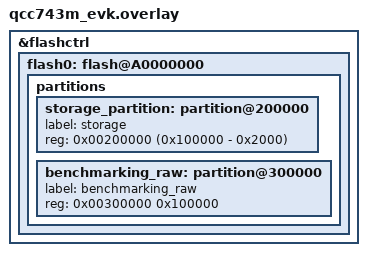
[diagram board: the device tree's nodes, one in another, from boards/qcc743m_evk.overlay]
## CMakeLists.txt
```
# Copyright (c) 2026 Qualcomm Technologies, Inc. and/or its subsidiaries
# SPDX-License-Identifier: BSD-3-Clause

cmake_minimum_required(VERSION 3.20.0)
find_package(Zephyr REQUIRED HINTS $ENV{ZEPHYR_BASE})
project(demo_fs)

target_sources(app PRIVATE src/main.c)
target_sources(app PRIVATE src/flash_littlefs.c)
target_sources(app PRIVATE src/flash_raw.c)
```

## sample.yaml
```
# Copyright (c) 2026 Qualcomm Technologies, Inc. and/or its subsidiaries
# SPDX-License-Identifier: Apache-2.0

tests:
  qcc7xx.sample.filesystem.flash:
    build_only: true
    platform_allow:
      - qcc743m_evk
      - qcc744m_evk
      - qcc748m_evk
      - qcc75xm_evk
```

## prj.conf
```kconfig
# Copyright (c) 2026 Qualcomm Technologies, Inc. and/or its subsidiaries
# SPDX-License-Identifier: BSD-3-Clause

# General
CONFIG_COMPILER_COLOR_DIAGNOSTICS=y
CONFIG_NO_OPTIMIZATIONS=y
CONFIG_INIT_STACKS=y
CONFIG_REQUIRES_FULL_LIBC=y

# Enable logging
CONFIG_LOG=y
CONFIG_LOG_MODE_IMMEDIATE=y
CONFIG_CBPRINTF_FP_SUPPORT=y

# Filesystem
CONFIG_FLASH=y
CONFIG_FLASH_MAP=y
CONFIG_FILE_SYSTEM=y
CONFIG_FILE_SYSTEM_LITTLEFS=y
CONFIG_POSIX_FILE_SYSTEM=y
CONFIG_FLASH_LOG_LEVEL_ERR=y
```

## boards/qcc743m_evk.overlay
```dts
/*
 * Copyright (c) 2026 Qualcomm Technologies, Inc. and/or its subsidiaries
 *
 * SPDX-License-Identifier: BSD-3-Clause
 */
 
/delete-node/ &storage_partition;
&flashctrl {
	flash0: flash@A0000000 {
		partitions {
			storage_partition: partition@200000 {
				label = "storage";
				reg = <0x00200000 (0x100000 - 0x2000)>;
			};
			benchmarking_raw: partition@300000 {
				label = "benchmarking_raw";
				reg = <0x00300000 0x100000>;
			};
		};
	};
};
```

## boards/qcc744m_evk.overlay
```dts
/*
 * Copyright (c) 2026 Qualcomm Technologies, Inc. and/or its subsidiaries
 *
 * SPDX-License-Identifier: BSD-3-Clause
 */
 
/delete-node/ &storage_partition;
&flashctrl {
	flash0: flash@A0000000 {
		partitions {
			storage_partition: partition@200000 {
				label = "storage";
				reg = <0x00200000 (0x300000 - 0x2000)>;
			};
			benchmarking_raw: partition@500000 {
				label = "benchmarking_raw";
				reg = <0x00500000 0x00300000>;
			};
		};
	};
};
```

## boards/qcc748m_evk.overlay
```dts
/*
 * Copyright (c) 2026 Qualcomm Technologies, Inc. and/or its subsidiaries
 *
 * SPDX-License-Identifier: BSD-3-Clause
 */

/*
 * qcc748m_evk flash layout (8MB - 8KB total):
 *   @000000  boot         64KB
 *   @010000  slot0        1344KB   ends @15FFFF
 *   @1F0000  slot1        1344KB   ends @33FFFF
 *   @3C0000  storage      128KB   (deleted below, re-created at larger address)
 *   @3E0000  scratch      64KB
 *   @3F0000  coredump     4KB
 *   @3F1000  ----FREE---- ~4MB
 *
 * This sample uses the free region above @400000 so as not to conflict
 * with the MCUboot image slots or scratch partition.
 * storage_partition @400000 2MB  – LittleFS test area
 * benchmarking_raw  @600000 1MB  – raw flash benchmark area
 */

/delete-node/ &storage_partition;

&flash0 {
	partitions {
		storage_partition: partition@400000 {
			label = "storage";
			reg = <0x00400000 DT_SIZE_M(2)>;
		};
		benchmarking_raw: partition@600000 {
			label = "benchmarking_raw";
			reg = <0x00600000 DT_SIZE_M(1)>;
		};
	};
};
```

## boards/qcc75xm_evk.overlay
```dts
/*
 * Copyright (c) 2026 Qualcomm Technologies, Inc. and/or its subsidiaries
 *
 * SPDX-License-Identifier: BSD-3-Clause
 */
 
/delete-node/ &storage_partition;
&flashctrl {
	flash0: flash@80000000 {
		partitions {
			storage_partition: partition@200000 {
				label = "storage";
				reg = <0x00200000 (0x100000 - 0x2000)>;
			};
			benchmarking_raw: partition@300000 {
				label = "benchmarking_raw";
				reg = <0x00300000 0x100000>;
			};
		};
	};
};
```

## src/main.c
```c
/*
 * Copyright (c) 2026 Qualcomm Technologies, Inc. and/or its subsidiaries
 * SPDX-License-Identifier: Apache-2.0
 */

#include <zephyr/kernel.h>

int main(void)
{
	extern int test_littlefs(void);
	test_littlefs();

	extern int test_raw(void);
	test_raw();

	return 0;
}
```

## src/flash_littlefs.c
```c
/*
 * Copyright (c) 2026 Qualcomm Technologies, Inc. and/or its subsidiaries
 * SPDX-License-Identifier: BSD-3-Clause
 */

#include <stdio.h>
#include <string.h>
#include <zephyr/fs/fs.h>
#include <zephyr/fs/littlefs.h>
#include <zephyr/kernel.h>
#include <zephyr/logging/log.h>
#include <zephyr/storage/flash_map.h>

LOG_MODULE_REGISTER(littlefs_test, LOG_LEVEL_INF);

/* Configuration */
#define MAX_PATH_LEN  255
#define FILE_SIZE     (6 * 1024) /* 6KB */
#define MOUNT_POINT   "/lfs"
#define THREAD1_DIR   MOUNT_POINT "/thread1"
#define THREAD2_DIR   MOUNT_POINT "/thread2"
#define PATTERN_BYTE  0xA5 /* Pattern for file content verification */
#define PATTERN1_BYTE 0x5A /* Pattern for file content verification */

/* File system configuration */
FS_LITTLEFS_DECLARE_DEFAULT_CONFIG(storage);
static struct fs_mount_t lfs_mnt = {
	.type = FS_LITTLEFS,
	.fs_data = &storage,
	.storage_dev = (void *)FIXED_PARTITION_ID(storage_partition),
	.mnt_point = MOUNT_POINT,
};

/* Callback function to print flash partition details */
static void print_partition(const struct flash_area *area, void *user_data)
{
	LOG_INF("Partition %s: offset=0x%lx, size=%u bytes",
		area->fa_dev->name ? area->fa_dev->name : "unknown", area->fa_off, area->fa_size);
}

/* Function to list all files in a given path */
static int list_files(const char *path)
{
	struct fs_dir_t dirp;
	struct fs_dirent entry;
	int rc;

	fs_dir_t_init(&dirp);
	rc = fs_opendir(&dirp, path);
	if (rc < 0) {
		LOG_ERR("Failed to open directory %s: %d", path, rc);
		return rc;
	}

	LOG_INF("Files in %s:", path);
	while (true) {
		rc = fs_readdir(&dirp, &entry);
		if (rc < 0) {
			LOG_ERR("Error reading directory %s: %d", path, rc);
			fs_closedir(&dirp);
			return rc;
		}
		if (entry.name[0] == 0) {
			break; /* End of directory */
		}
		if (entry.type == FS_DIR_ENTRY_FILE) {
			LOG_INF("  %s", entry.name);
		}
	}

	fs_closedir(&dirp);
	return 0;
}

/* Function to list all directories in a given path */
static int list_directories(const char *path)
{
	struct fs_dir_t dirp;
	struct fs_dirent entry;
	int rc;

	fs_dir_t_init(&dirp);
	rc = fs_opendir(&dirp, path);
	if (rc < 0) {
		LOG_ERR("Failed to open directory %s: %d", path, rc);
		return rc;
	}

	LOG_INF("Directories in %s:", path);
	while (true) {
		rc = fs_readdir(&dirp, &entry);
		if (rc < 0) {
			LOG_ERR("Error reading directory %s: %d", path, rc);
			fs_closedir(&dirp);
			return rc;
		}
		if (entry.name[0] == 0) {
			break; /* End of directory */
		}
		if (entry.type == FS_DIR_ENTRY_DIR) {
			LOG_INF("  %s", entry.name);
		}
	}

	fs_closedir(&dirp);

	return 0;
}

/* Function to create a directory if it doesn't exist */
static int create_directory(const char *path)
{
	struct fs_dir_t dir;
	int rc;

	fs_dir_t_init(&dir);
	rc = fs_opendir(&dir, path);
	if (rc == -ENOENT) {
		rc = fs_mkdir(path);
		if (rc < 0) {
			LOG_ERR("Failed to create directory %s: %d", path, rc);
			return rc;
		}
		LOG_INF("Created directory %s", path);
	} else if (rc < 0) {
		LOG_ERR("Error opening directory %s: %d", path, rc);
		fs_closedir(&dir);
		return rc;
	}
	fs_closedir(&dir);
	return 0;
}

/* Function to create a file with a pattern and verify its content */
static int create_and_verify_file(const char *dir, int file_num, uint8_t pattern)
{
	static char fname[MAX_PATH_LEN];
	struct fs_file_t file;
	static uint8_t write_buf[FILE_SIZE];
	static uint8_t read_buf[FILE_SIZE];
	int rc;

	/* Initialize file */
	fs_file_t_init(&file);
	snprintf(fname, sizeof(fname), "%s/file_%d.bin", dir, file_num);

	/* Fill write buffer with pattern */
	memset(write_buf, pattern, FILE_SIZE);

	/* Create and write file */
	rc = fs_open(&file, fname, FS_O_CREATE | FS_O_WRITE);
	if (rc < 0) {
		LOG_ERR("Failed to open %s for writing: %d", fname, rc);
		return rc;
	}

	rc = fs_write(&file, write_buf, FILE_SIZE);
	if (rc != FILE_SIZE) {
		LOG_ERR("Failed to write %s: wrote %d bytes, expected %d, error %d", fname, rc,
			FILE_SIZE, rc < 0 ? rc : 0);
		fs_close(&file);
		return rc < 0 ? rc : -EIO;
	}

	rc = fs_close(&file);
	if (rc < 0) {
		LOG_ERR("Failed to close %s after writing: %d", fname, rc);
		return rc;
	}

	/* Verify file content */
	rc = fs_open(&file, fname, FS_O_READ);
	if (rc < 0) {
		LOG_ERR("Failed to open %s for reading: %d", fname, rc);
		return rc;
	}

	rc = fs_read(&file, read_buf, FILE_SIZE);
	if (rc != FILE_SIZE) {
		LOG_ERR("Failed to read %s: read %d bytes, expected %d, error %d", fname, rc,
			FILE_SIZE, rc < 0 ? rc : 0);
		fs_close(&file);
		return rc < 0 ? rc : -EIO;
	}

	for (int i = 0; i < FILE_SIZE; i++) {
		if (read_buf[i] != pattern) {
			LOG_ERR("Verification failed for %s at byte %d: got 0x%02x, expected "
				"0x%02x",
				fname, i, read_buf[i], pattern);
			fs_close(&file);
			return -EIO;
		}
	}

	rc = fs_close(&file);
	if (rc < 0) {
		LOG_ERR("Failed to close %s after reading: %d", fname, rc);
		return rc;
	}

	LOG_INF("Created and verified %s", fname);

	return 0;
}

/* Function to delete all files in a directory */
static int delete_all_files(const char *dir)
{
	struct fs_dir_t dirp;
	struct fs_dirent entry;
	static char fname[MAX_PATH_LEN + 16];
	int rc;

	fs_dir_t_init(&dirp);
	rc = fs_opendir(&dirp, dir);
	if (rc < 0) {
		LOG_ERR("Failed to open directory %s: %d", dir, rc);
		return rc;
	}

	while (true) {
		rc = fs_readdir(&dirp, &entry);
		if (rc < 0) {
			LOG_ERR("Error reading directory %s: %d", dir, rc);
			fs_closedir(&dirp);
			return rc;
		}
		if (entry.name[0] == 0) {
			break; /* End of directory */
		}
		if (entry.type != FS_DIR_ENTRY_FILE) {
			continue; /* Skip subdirectories */
		}

		snprintf(fname, sizeof(fname), "%s/%s", dir, entry.name);
		rc = fs_unlink(fname);
		if (rc < 0) {
			LOG_ERR("Failed to delete %s: %d", fname, rc);
			fs_closedir(&dirp);
			return rc;
		}
		LOG_INF("Deleted %s", fname);
	}

	fs_closedir(&dirp);

	return 0;
}

/* Main function */
int test_littlefs(void)
{
	int rc;

	LOG_INF("Littlefs test started...");

	k_sleep(K_MSEC(50));

	/* Print all available flash partitions */
	LOG_INF("Available flash partitions:");
	flash_area_foreach(print_partition, NULL);

	/* Mount LittleFS */
	struct fs_dirent entry;
	int not_mounted = fs_stat(MOUNT_POINT, &entry);
	if (not_mounted) {
		rc = fs_mount(&lfs_mnt);
		if (rc < 0) {
			LOG_ERR("Failed to mount LittleFS: %d", rc);
			return rc;
		}
	}
	LOG_INF("LittleFS mounted successfully at %s", MOUNT_POINT);

	/* Create thread directories */
	rc = create_directory(THREAD1_DIR);
	if (rc < 0) {
		return rc;
	}
	rc = create_directory(THREAD2_DIR);
	if (rc < 0) {
		return rc;
	}

	/* List all directories in the mount point */
	rc = list_directories(MOUNT_POINT);
	if (rc < 0) {
		LOG_ERR("Failed to list directories at %s: %d", MOUNT_POINT, rc);
	}

	struct fs_statvfs sbuf;
	rc = fs_statvfs(MOUNT_POINT, &sbuf);
	if (rc >= 0) {
		LOG_INF("%s: bsize = %lu ; frsize = %lu ;"
			" blocks = %lu ; bfree = %lu",
			MOUNT_POINT, sbuf.f_bsize, sbuf.f_frsize, sbuf.f_blocks, sbuf.f_bfree);
	}

	k_sleep(K_MSEC(50));

	create_and_verify_file((void *)THREAD1_DIR, 0, PATTERN_BYTE);
	create_and_verify_file((void *)THREAD2_DIR, 0, PATTERN1_BYTE);
	create_and_verify_file((void *)THREAD1_DIR, 1, PATTERN_BYTE);
	create_and_verify_file((void *)THREAD2_DIR, 1, PATTERN1_BYTE);
	create_and_verify_file((void *)THREAD1_DIR, 77, PATTERN_BYTE);
	create_and_verify_file((void *)THREAD2_DIR, 77, PATTERN1_BYTE);
	create_and_verify_file((void *)THREAD1_DIR, 200, PATTERN_BYTE);
	create_and_verify_file((void *)THREAD2_DIR, 200, PATTERN1_BYTE);
	create_and_verify_file((void *)THREAD1_DIR, 999, PATTERN_BYTE);
	create_and_verify_file((void *)THREAD2_DIR, 999, PATTERN1_BYTE);

	k_sleep(K_MSEC(100));

	/* List all files */
	rc = list_files(THREAD1_DIR);
	if (rc < 0) {
		LOG_ERR("Failed to list files at %s: %d", THREAD1_DIR, rc);
	}

	/* List all files */
	rc = list_directories(THREAD2_DIR);
	if (rc < 0) {
		LOG_ERR("Failed to list files at %s: %d", THREAD2_DIR, rc);
	}

	k_sleep(K_MSEC(100));

	rc = delete_all_files(THREAD1_DIR);
	if (rc < 0) {
		LOG_ERR("Dir %s: Error deleting files: %d", THREAD1_DIR, rc);
	}

	/* List all files */
	rc = list_files(THREAD1_DIR);
	if (rc < 0) {
		LOG_ERR("Failed to list files at %s: %d", THREAD1_DIR, rc);
	}

	/* List all directories */
	rc = list_files(THREAD2_DIR);
	if (rc < 0) {
		LOG_ERR("Failed to list files at %s: %d", THREAD2_DIR, rc);
	}

	LOG_INF("Littlefs test ended !");

	return 0;
}
```

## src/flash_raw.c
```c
/*
 * Copyright (c) 2026 Qualcomm Technologies, Inc. and/or its subsidiaries
 * SPDX-License-Identifier: BSD-3-Clause
 */

#include <zephyr/device.h>
#include <zephyr/drivers/flash.h>
#include <zephyr/kernel.h>
#include <zephyr/logging/log.h>
#include <zephyr/storage/flash_map.h>

LOG_MODULE_REGISTER(rawfs_test, LOG_LEVEL_INF);

#define BLOCK_SIZE   (256) /* Min write block  and align boundary */
#define PATTERN_BYTE 0xA5  /* Pattern for write and verification */

static const struct flash_area *fa_raw = NULL;
static const struct flash_parameters *fp = NULL;
static uint8_t write_buf[BLOCK_SIZE];
static uint8_t read_buf[BLOCK_SIZE];

/* Callback function to print flash partition details */
static void print_partition(const struct flash_area *area, void *user_data)
{
	LOG_INF("Partition %s: offset=0x%lx, size=%u bytes",
		area->fa_dev->name ? area->fa_dev->name : "unknown", area->fa_off, area->fa_size);
}

static int flash_raw_init(void)
{
	int rc = 0;

	if (!fa_raw) {
		rc = flash_area_open(FIXED_PARTITION_ID(benchmarking_raw), &fa_raw);
		fp = flash_get_parameters(fa_raw->fa_dev);
		if (!fp) {
			LOG_ERR("Failed to get flash parameters for device %s",
				fa_raw->fa_dev->name);
			// flash_area_close(fa_raw);
		} else {
			LOG_INF("Flash write constraints for partition %s:", fa_raw->fa_dev->name);
			LOG_INF("  Minimal write size: %u bytes", fp->write_block_size);
			LOG_INF("  Write alignment: offset and length must be multiples of %u "
				"bytes",
				fp->write_block_size);
			LOG_INF("  Partition size: %u bytes", fa_raw->fa_size);
		}
	}
	return rc;
}

static int flash_raw_erase(uint32_t offset, uint32_t size)
{
	int ret = 0;

	size_t sector_size = 0x1000;

	/* do not erase if offset is in middle of section ! */
	uint32_t offset_roundup = ROUND_UP(offset, sector_size);

	uint32_t size_to_erase = 0;
	if (offset + size >= offset_roundup) {
		size_to_erase = ROUND_UP(size - (offset_roundup - offset), sector_size);
	} else if ((offset % sector_size) == 0) {
		size_to_erase = ROUND_UP(size, sector_size);
	} else {
		return 0;
	}

	/* Erase whole raw partition */
	ret = flash_area_erase(fa_raw, (off_t)offset_roundup, size_to_erase);

	return ret;
}

static int flash_raw_mount()
{
	int ret = 0;

	ret = flash_raw_init();
	if (!ret) {
		LOG_INF("RawFS erasing at once starts ...");
		ret = flash_raw_erase(0, fa_raw->fa_size);
	}

	return ret;
}

/* Main function */
int test_raw(void)
{

	int rc = 0;

	printk("\n");
	LOG_INF("Rawfs test started...");

	/* Print all available flash partitions */
	LOG_INF("Available flash partitions:");
	flash_area_foreach(print_partition, NULL);

	/* Mount raw partition */
	rc = flash_raw_mount();
	if (rc) {
		LOG_ERR("RawFS mount failed !");
		return rc;
	}

	LOG_INF("RawFS mounted successfully !");
	LOG_INF("RawFS erasing at once starts ...");

	/* Erase whole partition */
	rc = flash_raw_erase(0, fa_raw->fa_size);
	if (rc) {
		LOG_ERR("RawFS erase failed !");
		return rc;
	}

	LOG_INF("RawFS erased successfully !");

	/* Overwrite whole partition */
	uint32_t blocks = fa_raw->fa_size / BLOCK_SIZE;
	memset(write_buf, PATTERN_BYTE, BLOCK_SIZE);
	for (uint32_t i = 0; i < blocks; i++) {
		/* Write block */
		off_t offset = i * BLOCK_SIZE;
		rc = flash_area_write(fa_raw, offset, write_buf, BLOCK_SIZE);
		if (rc < 0) {
			LOG_ERR("Failed to write at offset 0x%lx: %d", offset, rc);
			return rc;
		}

		if (i % 1000 == 0 && i) {
			LOG_INF("%d blocks are written ...", i);
		}
	}

	LOG_INF("RawFS %d blocks ( bs %d bytes ) written successfully !", blocks, BLOCK_SIZE);

	/* Read and verify */
	for (uint32_t i = 0; i < blocks; i++) {
		/* Read block */
		off_t offset = i * BLOCK_SIZE;
		rc = flash_area_read(fa_raw, offset, read_buf, BLOCK_SIZE);
		if (rc < 0) {
			LOG_ERR("Failed to read at offset 0x%lx: %d", offset, rc);
			return rc;
		}
		/* Verify */
		for (size_t j = 0; j < BLOCK_SIZE; j++) {
			if (read_buf[j] != PATTERN_BYTE) {
				LOG_ERR("Verification failed at offset 0x%lx + %u: got 0x%02x, "
					"expected 0x%02x",
					offset, j, read_buf[j], PATTERN_BYTE);
				return -EIO;
			}
		}
	}

	LOG_INF("RawFS %d blocks ( bs %d bytes ) read and verified successfully !", blocks,
		BLOCK_SIZE);

	LOG_INF("Rawfs test ended !");

	return 0;
}
```
